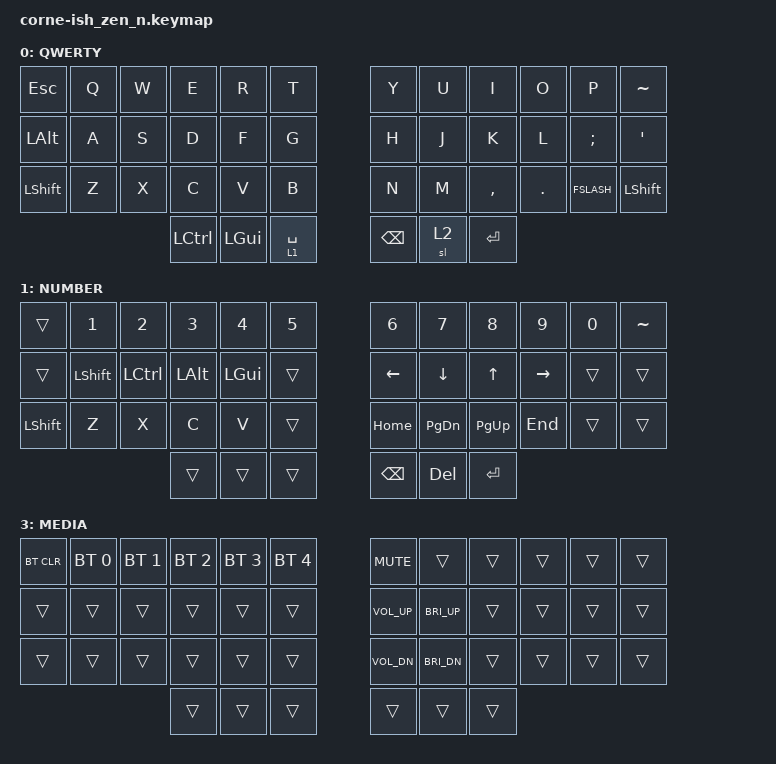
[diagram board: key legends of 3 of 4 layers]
/*
*
* Copyright (c) 2021 lowprokb.ca
* SPDX-License-Identifier: MIT
*
*/

#include <behaviors.dtsi>
#include <dt-bindings/zmk/keys.h>
#include <dt-bindings/zmk/bt.h>

#define QWERTY 0
#define NUMBER 1
#define SYMBOL 2
#define MEDIA  3
/ {

  combos {
    #include "combos.dtsi"
  };

/ {
  keymap {
    compatible = "zmk,keymap";

    base_layer {
      label = "QWERTY";
      bindings = <
        // ╭─────────────┬─────────────┬─────────────┬─────────────┬─────────────┬─────────────╮   ╭─────────────┬─────────────┬─────────────┬─────────────┬─────────────┬─────────────╮
             &kp ESC       &kp Q         &kp W         &kp E         &kp R         &kp T             &kp Y         &kp U         &kp I         &kp O         &kp P         &kp TILDE
        // ├─────────────├─────────────┼─────────────┼─────────────┼─────────────┼─────────────┤   ├─────────────┼─────────────┼─────────────┼─────────────┼─────────────┤─────────────┤
             &kp LALT      &kp A         &kp S         &kp D         &kp F         &kp G             &kp H         &kp J         &kp K         &kp L         &kp SEMI      &kp SQT
        // ├─────────────├─────────────┼─────────────┼─────────────┼─────────────┼─────────────┤   ├─────────────┼─────────────┼─────────────┼─────────────┼─────────────┤─────────────┤
             &kp LSHFT     &kp Z         &kp X         &kp C         &kp V         &kp B             &kp N         &kp M         &kp COMMA     &kp DOT       &kp FSLASH    &kp LSHFT
        // ╰─────────────┴─────────────┴─────────────┴─────────────┼─────────────┼─────────────┤   ├─────────────┼─────────────┼─────────────┴─────────────┴─────────────┤─────────────╯
                                                       &kp LCTRL      &kp LGUI     &lt 1 SPACE       &kp BSPC      &sl 2         &kp ENTER
        //                                           ╰─────────────┴─────────────┴─────────────╯   ╰─────────────┴─────────────┴─────────────╯
      >;
    };

    number_layer {
      label = "NUMBER";
      bindings = <
        // ╭─────────────┬─────────────┬─────────────┬─────────────┬─────────────┬─────────────╮   ╭─────────────┬─────────────┬─────────────┬─────────────┬─────────────┬─────────────╮
             &trans        &kp N1        &kp N2        &kp N3        &kp N4        &kp N5            &kp N6        &kp N7        &kp N8        &kp N9        &kp N0        &kp TILDE
        // ├─────────────├─────────────┼─────────────┼─────────────┼─────────────┼─────────────┤   ├─────────────┼─────────────┼─────────────┼─────────────┼─────────────┤─────────────┤
             &trans        &kp LSHFT     &kp LCTRL     &kp LALT      &kp LGUI      &trans            &kp LEFT      &kp DOWN      &kp UP        &kp RIGHT     &trans        &trans 
        // ├─────────────├─────────────┼─────────────┼─────────────┼─────────────┼─────────────┤   ├─────────────┼─────────────┼─────────────┼─────────────┼─────────────┤─────────────┤
             &kp LSHFT     &kp Z         &kp X         &kp C         &kp V         &trans            &kp HOME      &kp PG_DN     &kp PG_UP     &kp END       &trans        &trans
        // ╰─────────────┴─────────────┴─────────────┴─────────────┼─────────────┼─────────────┤   ├─────────────┼─────────────┼─────────────┴─────────────┴─────────────┤─────────────╯
                                                       &trans        &trans        &trans            &kp BSPC      &kp DEL       &kp ENTER
        //                                           ╰─────────────┴─────────────┴─────────────╯   ╰─────────────┴─────────────┴─────────────╯
      >;
    };

    symbol_layer {
      label = "SYMBOL";
      bindings = <
        // ╭─────────────┬─────────────┬─────────────┬─────────────┬─────────────┬─────────────╮   ╭─────────────┬─────────────┬─────────────┬─────────────┬─────────────┬─────────────╮
             &trans        &kp EXCL      &kp AT        &kp HASH      &kp DLLR      &kp PRCNT         &kp CARET     &kp AMPS      &kp ASTRK     &kp LPAR      &kp RPAR      &kp BSLH
        // ├─────────────├─────────────┼─────────────┼─────────────┼─────────────┼─────────────┤   ├─────────────┼─────────────┼─────────────┼─────────────┼─────────────┤─────────────┤
             &mo 3         &bt BT_SEL 0  &bt BT_SEL 1  &bt BT_SEL 2  &kp GRAVE     &trans            &kp MINUS     &kp EQUAL     &kp LPAR      &kp RPAR      &kp TILDE     &kp PIPE     
        // ├─────────────├─────────────┼─────────────┼─────────────┼─────────────┼─────────────┤   ├─────────────┼─────────────┼─────────────┼─────────────┼─────────────┤─────────────┤
             &kp SHFT      &kp F1        &kp F2        &kp F5        &kp F6        &kp F10           &kp UNDER     &kp PLUS      &kp LBKT      &kp RBKT      &kp LBRC      &kp RBRC
        // ╰─────────────┴─────────────┴─────────────┴─────────────┼─────────────┼─────────────┤   ├─────────────┼─────────────┼─────────────┴─────────────┴─────────────┤─────────────╯
                                                       &kp LCTRL      &kp LGUI     kp SPACE          &kp BSPC      &kp DEL       &kp ENTER
        //                                           ╰─────────────┴─────────────┴─────────────╯   ╰─────────────┴─────────────┴─────────────╯
      >;
    };

    media_layer {
      label = "MEDIA";
      bindings = <
        // ╭─────────────┬─────────────┬─────────────┬─────────────┬─────────────┬─────────────╮   ╭─────────────┬─────────────┬─────────────┬─────────────┬─────────────┬─────────────╮
             &bt BT_CLR    &bt BT_SEL 0  &bt BT_SEL 1  &bt BT_SEL 2  &bt BT_SEL 3  &bt BT_SEL 4      &kp K_MUTE    &trans        &trans        &trans        &trans        &trans 
        // ├─────────────├─────────────┼─────────────┼─────────────┼─────────────┼─────────────┤   ├─────────────┼─────────────┼─────────────┼─────────────┼─────────────┤─────────────┤
             &trans        &trans        &trans        &trans        &trans        &trans            &kp C_VOL_UP  &kp C_BRI_UP  &trans        &trans        &trans        &trans 
        // ├─────────────├─────────────┼─────────────┼─────────────┼─────────────┼─────────────┤   ├─────────────┼─────────────┼─────────────┼─────────────┼─────────────┤─────────────┤
             &trans        &trans        &trans        &trans        &trans        &trans            &kp C_VOL_DN  &kp C_BRI_DN  &trans        &trans        &trans        &trans 
        // ╰─────────────┴─────────────┴─────────────┴─────────────┼─────────────┼─────────────┤   ├─────────────┼─────────────┼─────────────┴─────────────┴─────────────┤─────────────╯
                                                       &trans        &trans        &trans            &trans        &trans        &trans  
        //                                           ╰─────────────┴─────────────┴─────────────╯   ╰─────────────┴─────────────┴─────────────╯
      >;
    };
};
